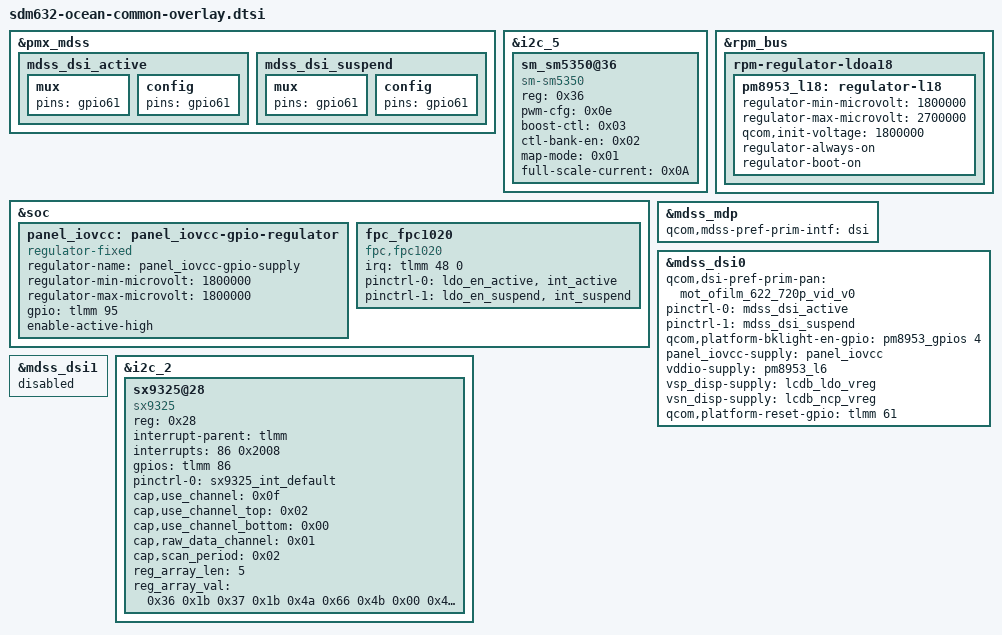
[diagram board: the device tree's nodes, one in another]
/*
 * Copyright (c) 2018, The Linux Foundation. All rights reserved.
 *
 * This program is free software; you can redistribute it and/or modify
 * it under the terms of the GNU General Public License version 2 and
 * only version 2 as published by the Free Software Foundation.
 *
 * This program is distributed in the hope that it will be useful,
 * but WITHOUT ANY WARRANTY; without even the implied warranty of
 * MERCHANTABILITY or FITNESS FOR A PARTICULAR PURPOSE.  See the
 * GNU General Public License for more details.
 */

#include "sdm632-moto-common-overlay.dtsi"
#include "sdm632-ocean-pinctrl-overlay.dtsi"
#include "dsi-panel-mot-ofilm-622-720p-vid.dtsi"
#include "dsi-panel-mot-dummy-qhd-video.dtsi"
#include "sdm632-camera-sensor-mot-ocean-overlay.dtsi"

&pmx_mdss {
	mdss_dsi_active {
		mux {
			pins = "gpio61";
		};

		config {
			pins = "gpio61";
		};
	};

	mdss_dsi_suspend {
		mux {
			pins = "gpio61";
		};

		config {
			pins = "gpio61";
		};
	};

};

&i2c_5 {
	status = "ok";
	sm_sm5350@36 {
		compatible = "sm-sm5350";
		reg = <0x36>;
		pwm-cfg = <0x0e>;
		boost-ctl = <0x03>;
		ctl-bank-en = <0x02>;
		map-mode = <0x01>;
		/* fsc = 5 + 0.8 * value */
		full-scale-current = <0x0A>;
	};
};

&soc {
	panel_iovcc: panel_iovcc-gpio-regulator {
		compatible = "regulator-fixed";
		regulator-name = "panel_iovcc-gpio-supply";
		regulator-min-microvolt = <1800000>;
		regulator-max-microvolt = <1800000>;
		gpio = <&tlmm 95 0>;
		enable-active-high;
	};
};

&rpm_bus {
	rpm-regulator-ldoa18 {
		status = "okay";
		pm8953_l18: regulator-l18 {
			regulator-min-microvolt = <1800000>;
			regulator-max-microvolt = <2700000>;
			qcom,init-voltage = <1800000>;
			status = "okay";
			regulator-always-on;
			regulator-boot-on;
		};
	};
};

&mdss_mdp {
	qcom,mdss-pref-prim-intf = "dsi";
};

&mdss_dsi0 {
	qcom,dsi-pref-prim-pan = <&mot_ofilm_622_720p_vid_v0>;

	pinctrl-names = "mdss_default", "mdss_sleep";
	pinctrl-0 = <&mdss_dsi_active>;
	pinctrl-1 = <&mdss_dsi_suspend>;

	qcom,platform-bklight-en-gpio = <&pm8953_gpios 4 0>;

	panel_iovcc-supply = <&panel_iovcc>;
	vddio-supply = <&pm8953_l6>;
	vsp_disp-supply = <&lcdb_ldo_vreg>;
	vsn_disp-supply = <&lcdb_ncp_vreg>;

	qcom,platform-reset-gpio = <&tlmm 61 0>;
};

&mdss_dsi1 {
	status = "disabled";
};

&i2c_2 {
	status = "ok";
	sx9325@28 {
		compatible = "sx9325";
		reg = <0x28>;
		//cap_vdd-supply = <&pm8953_l18>;
		//cap_svdd-supply = <&pm8953_l14>;
		interrupt-parent = <&tlmm>;
		interrupts = <86 0x2008>;
		gpios = <&tlmm 86 0x2008>; /* IRQ */
		pinctrl-names = "default";
		pinctrl-0 = <&sx9325_int_default>;
		cap,use_channel = <0x0f>;
		cap,use_channel_top = <0x02>;
		cap,use_channel_bottom = <0x00>;
		cap,raw_data_channel = <0x01>;
		cap,scan_period = <0x02>;
		reg_array_len = <5>;
		reg_array_val = <0x36 0x1b 0x37 0x1b 0x4a 0x66 0x4b 0x00 0x4c 0x00>;
	};
};

&soc {
	fpc_fpc1020{
		compatible = "fpc,fpc1020";
		status = "ok";
		irq = <&tlmm 48 0>;

		pinctrl-names = "default", "suspend";
		pinctrl-0 = <&ldo_en_active &int_active>;
		pinctrl-1 = <&ldo_en_suspend &int_suspend>;
	};
};
